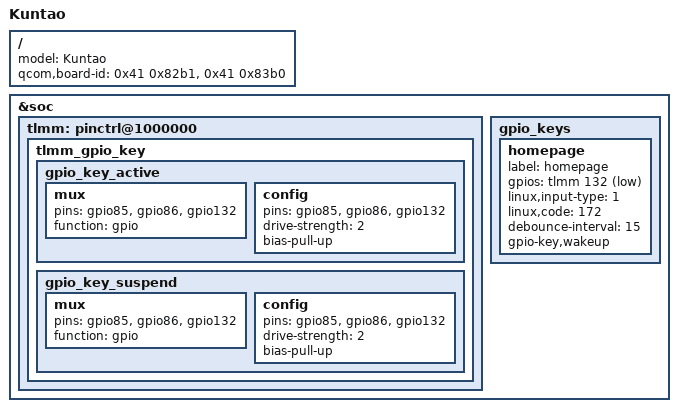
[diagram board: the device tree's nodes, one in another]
/*
 * Copyright (c) 2015-2016, The Linux Foundation. All rights reserved.
 *
 * This program is free software; you can redistribute it and/or modify
 * it under the terms of the GNU General Public License version 2 and
 * only version 2 as published by the Free Software Foundation.
 *
 * This program is distributed in the hope that it will be useful,
 * but WITHOUT ANY WARRANTY; without even the implied warranty of
 * MERCHANTABILITY or FITNESS FOR A PARTICULAR PURPOSE.  See the
 * GNU General Public License for more details.
 */

/dts-v1/;

#include "msm8953-lenovo-common.dtsi"

/ {
	model = "Kuntao";
	qcom,board-id= <0x41 0x82b1>, <0x41 0x83b0>;  //for dvt2-2,pvt...
};


&soc {
	tlmm: pinctrl@1000000 {
		tlmm_gpio_key {
			gpio_key_active: gpio_key_active {
				mux {
					pins = "gpio85", "gpio86", "gpio132";
					function = "gpio";
				};

				config {
					pins = "gpio85", "gpio86", "gpio132";
					drive-strength = <2>;
					bias-pull-up;
				};
			};

			gpio_key_suspend: gpio_key_suspend {
				mux {
					pins = "gpio85", "gpio86","gpio132";
					function = "gpio";
				};

				config {
					pins = "gpio85", "gpio86", "gpio132";
					drive-strength = <2>;
					bias-pull-up;
				};
			};
		};
	};
	gpio_keys {
		homepage {
			label = "homepage";
			gpios = <&tlmm 132 0x1>;
			linux,input-type = <1>;
			linux,code = <172>;
			debounce-interval = <15>;
			gpio-key,wakeup;
		};
	};
};

